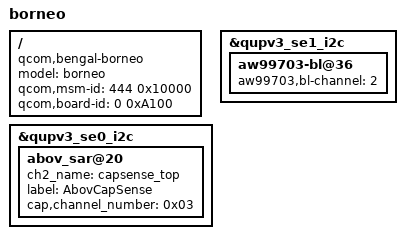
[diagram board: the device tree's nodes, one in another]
/* Copyright (c) 2020, The Linux Foundation. All rights reserved.
 *
 * This program is free software; you can redistribute it and/or modify
 * it under the terms of the GNU General Public License version 2 and
 * only version 2 as published by the Free Software Foundation.
 *
 * This program is distributed in the hope that it will be useful,
 * but WITHOUT ANY WARRANTY; without even the implied warranty of
 * MERCHANTABILITY or FITNESS FOR A PARTICULAR PURPOSE.  See the
 * GNU General Public License for more details.
 */

/dts-v1/;
/plugin/;

#include "bengal-borneo-common-overlay.dtsi"

/ {
	model = "borneo";
	compatible = "qcom,bengal-borneo", "qcom,bengal-moto", "qcom,bengal";
	qcom,msm-id = <444 0x10000>;
	qcom,board-id = <0 0xA100>;
};

/*
 * Borneo HW rev specific changes go here
 */

&qupv3_se0_i2c {
    abov_sar@20 {
        ch2_name = "capsense_top";
        label = "AbovCapSense";
        cap,channel_number = <0x03>;
    };
};

&qupv3_se1_i2c {
    aw99703-bl@36 {
        aw99703,bl-channel = <2>;
    };
};
